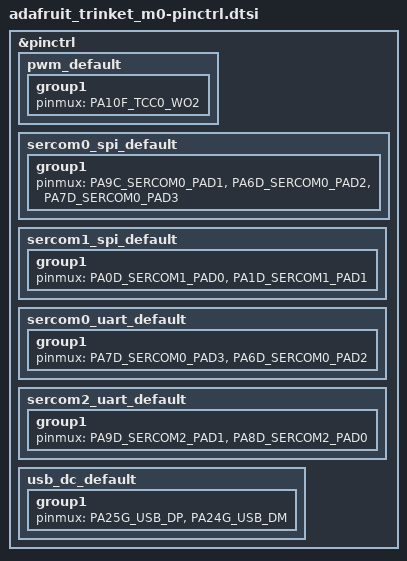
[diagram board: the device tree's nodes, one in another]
/*
 * Copyright (c) 2022, Gerson Fernando Budke <nandojve@gmail.com>
 * SPDX-License-Identifier: Apache-2.0
 */

#include <dt-bindings/pinctrl/samd21-da1eXabcd-pinctrl.h>

&pinctrl {
	pwm_default: pwm_default {
		group1 {
			pinmux = <PA10F_TCC0_WO2>;
		};
	};

	sercom0_spi_default: sercom0_spi_default {
		group1 {
			pinmux = <PA9C_SERCOM0_PAD1>,
				 <PA6D_SERCOM0_PAD2>,
				 <PA7D_SERCOM0_PAD3>;
		};
	};
	sercom1_spi_default: sercom1_spi_default {
		group1 {
			pinmux = <PA0D_SERCOM1_PAD0>,
				 <PA1D_SERCOM1_PAD1>;
		};
	};

	sercom0_uart_default: sercom0_uart_default {
		group1 {
			pinmux = <PA7D_SERCOM0_PAD3>,
				 <PA6D_SERCOM0_PAD2>;
		};
	};
	sercom2_uart_default: sercom2_uart_default {
		group1 {
			pinmux = <PA9D_SERCOM2_PAD1>,
				 <PA8D_SERCOM2_PAD0>;
		};
	};

	usb_dc_default: usb_dc_default {
		group1 {
			pinmux = <PA25G_USB_DP>,
				 <PA24G_USB_DM>;
		};
	};
};
